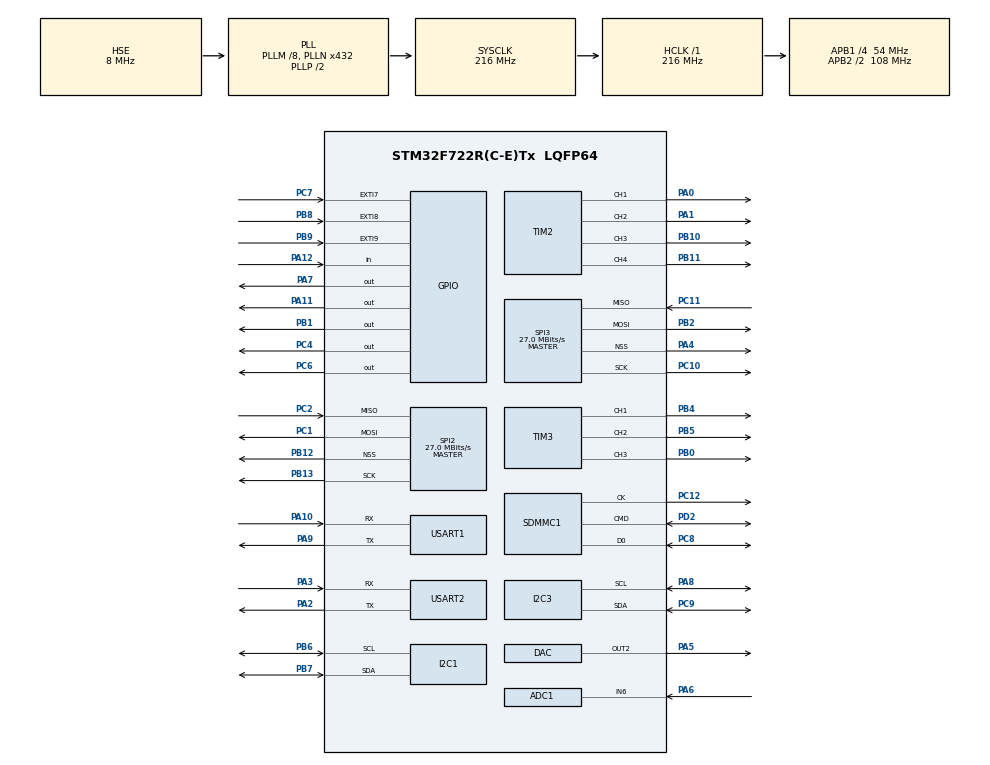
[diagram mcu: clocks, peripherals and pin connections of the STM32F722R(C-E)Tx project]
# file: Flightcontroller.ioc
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ADC1.Channel-1\#ChannelRegularConversion=ADC_CHANNEL_6
ADC1.NbrOfConversionFlag=1
ADC1.Rank-1\#ChannelRegularConversion=1
ADC1.SamplingTime-1\#ChannelRegularConversion=ADC_SAMPLETIME_3CYCLES
ADC1.master=1
I2C1.Timing=0x20404768
I2C3.Timing=0x20404768
Mcu.Family=STM32F7
Mcu.Name=STM32F722R(C-E)Tx
Mcu.Package=LQFP64
NVIC.PriorityGroup=NVIC_PRIORITYGROUP_4
PA0-WKUP.Signal=S_TIM2_CH1_ETR
PA1.Signal=S_TIM2_CH2
PA10.Mode=Asynchronous
PA10.Signal=USART1_RX
PA11.Signal=GPIO_Output
PA12.Signal=GPIO_Input
PA13.Mode=Serial_Wire
PA13.Signal=SYS_JTMS-SWDIO
PA14.Mode=Serial_Wire
PA14.Signal=SYS_JTCK-SWCLK
PA2.Mode=Asynchronous
PA2.Signal=USART2_TX
PA3.Mode=Asynchronous
PA3.Signal=USART2_RX
PA4.Mode=NSS_Signal_Hard_Output
PA4.Signal=SPI3_NSS
PA5.Signal=COMP_DAC2_group
PA6.Signal=ADCx_IN6
PA7.Signal=GPIO_Output
PA8.Mode=I2C
PA8.Signal=I2C3_SCL
PA9.Mode=Asynchronous
PA9.Signal=USART1_TX
PB0.Signal=S_TIM3_CH3
PB1.Signal=GPIO_Output
PB10.Signal=S_TIM2_CH3
PB11.Signal=S_TIM2_CH4
PB12.Mode=NSS_Signal_Hard_Output
PB12.Signal=SPI2_NSS
PB13.Mode=Full_Duplex_Master
PB13.Signal=SPI2_SCK
PB2.Mode=Full_Duplex_Master
PB2.Signal=SPI3_MOSI
PB4.Signal=S_TIM3_CH1
PB5.Signal=S_TIM3_CH2
PB6.Mode=I2C
PB6.Signal=I2C1_SCL
PB7.Mode=I2C
PB7.Signal=I2C1_SDA
PB8.Signal=GPXTI8
PB9.Signal=GPXTI9
PC1.Mode=Full_Duplex_Master
PC1.Signal=SPI2_MOSI
PC10.Mode=Full_Duplex_Master
PC10.Signal=SPI3_SCK
PC11.Mode=Full_Duplex_Master
PC11.Signal=SPI3_MISO
PC12.Mode=SD_1_bit
PC12.Signal=SDMMC1_CK
PC2.Mode=Full_Duplex_Master
PC2.Signal=SPI2_MISO
PC4.Signal=GPIO_Output
PC6.Signal=GPIO_Output
PC7.Signal=GPXTI7
PC8.Mode=SD_1_bit
PC8.Signal=SDMMC1_D0
PC9.Mode=I2C
PC9.Signal=I2C3_SDA
PD2.Mode=SD_1_bit
PD2.Signal=SDMMC1_CMD
PH0-OSC_IN.Mode=HSE-External-Oscillator
PH0-OSC_IN.Signal=RCC_OSC_IN
PH1-OSC_OUT.Mode=HSE-External-Oscillator
PH1-OSC_OUT.Signal=RCC_OSC_OUT
ProjectManager.HeapSize=0x200
ProjectManager.StackSize=0x400
ProjectManager.TargetToolchain=STM32CubeIDE
RCC.AHBFreq_Value=216000000
RCC.APB1CLKDivider=RCC_HCLK_DIV4
RCC.APB1Freq_Value=54000000
RCC.APB1TimFreq_Value=108000000
RCC.APB2CLKDivider=RCC_HCLK_DIV2
RCC.APB2Freq_Value=108000000
RCC.APB2TimFreq_Value=216000000
RCC.CortexFreq_Value=216000000
RCC.HCLKFreq_Value=216000000
RCC.HSE_VALUE=8000000
RCC.HSI_VALUE=16000000
RCC.LSE_VALUE=32768
RCC.PLLM=8
RCC.PLLN=432
RCC.PLLQ=9
RCC.PLLSourceVirtual=RCC_PLLSOURCE_HSE
RCC.SDMMCClockSelection=RCC_SDMMC1CLKSOURCE_CLK48
RCC.SYSCLKFreq_VALUE=216000000
RCC.SYSCLKSource=RCC_SYSCLKSOURCE_PLLCLK
RCC.USBFreq_Value=48000000
RCC.VCOOutputFreq_Value=432000000
SH.ADCx_IN6.0=ADC1_IN6,IN6
SH.COMP_DAC2_group.0=DAC_OUT2,DAC_OUT2
SH.S_TIM2_CH1_ETR.0=TIM2_CH1,PWM Generation1 CH1
SH.S_TIM2_CH2.0=TIM2_CH2,PWM Generation2 CH2
SH.S_TIM2_CH3.0=TIM2_CH3,PWM Generation3 CH3
SH.S_TIM2_CH4.0=TIM2_CH4,PWM Generation4 CH4
SH.S_TIM3_CH1.0=TIM3_CH1,PWM Generation1 CH1
SH.S_TIM3_CH2.0=TIM3_CH2,PWM Generation2 CH2
SH.S_TIM3_CH3.0=TIM3_CH3,PWM Generation3 CH3
SPI2.CalculateBaudRate=27.0 MBits/s
SPI2.Direction=SPI_DIRECTION_2LINES
SPI2.Mode=SPI_MODE_MASTER
SPI2.VirtualNSS=VM_NSSHARD
SPI2.VirtualType=VM_MASTER
SPI3.CalculateBaudRate=27.0 MBits/s
SPI3.Direction=SPI_DIRECTION_2LINES
SPI3.Mode=SPI_MODE_MASTER
SPI3.VirtualNSS=VM_NSSHARD
SPI3.VirtualType=VM_MASTER
TIM2.Channel-PWM\ Generation1\ CH1=TIM_CHANNEL_1
TIM2.Channel-PWM\ Generation2\ CH2=TIM_CHANNEL_2
TIM2.Channel-PWM\ Generation3\ CH3=TIM_CHANNEL_3
TIM2.Channel-PWM\ Generation4\ CH4=TIM_CHANNEL_4
TIM3.Channel-PWM\ Generation1\ CH1=TIM_CHANNEL_1
TIM3.Channel-PWM\ Generation2\ CH2=TIM_CHANNEL_2
TIM3.Channel-PWM\ Generation3\ CH3=TIM_CHANNEL_3
USART1.VirtualMode-Asynchronous=VM_ASYNC
USART2.VirtualMode-Asynchronous=VM_ASYNC
VP_FATFS_VS_SDIO.Mode=SDIO
VP_TIM2_VS_ClockSourceINT.Mode=Internal
board=custom

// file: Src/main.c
/* USER CODE BEGIN Header */
/**
  ******************************************************************************
  * @file           : main.c
  * @brief          : Main program body
  ******************************************************************************
  * @attention
  *
  * <h2><center>&copy; Copyright (c) 2019 STMicroelectronics.
  * All rights reserved.</center></h2>
  *
  * This software component is licensed by ST under BSD 3-Clause license,
  * the "License"; You may not use this file except in compliance with the
  * License. You may obtain a copy of the License at:
  *                        opensource.org/licenses/BSD-3-Clause
  *
  ******************************************************************************
  */
/* USER CODE END Header */

#include "main.h"
#include <stdio.h>
#include "adc.h"
#include "dac.h"
#include "fatfs.h"
#include "i2c.h"
#include "sdmmc.h"
#include "spi.h"
#include "tim.h"
#include "usart.h"
#include "gpio.h"

void SystemClock_Config(void);

int main(void)
{

  /* MCU Configuration--------------------------------------------------------*/

  /* Reset of all peripherals, Initializes the Flash interface and the Systick. */
  HAL_Init();

  /* Configure the system clock */
  SystemClock_Config();

  /* Initialize all configured peripherals */
  MX_GPIO_Init();
  MX_I2C1_Init();
  MX_SDMMC1_SD_Init();
  MX_SPI2_Init();
  MX_USART1_UART_Init();
  MX_USART2_UART_Init();
  MX_FATFS_Init();
  MX_I2C3_Init();
  MX_TIM2_Init();
  MX_DAC_Init();
  MX_SPI3_Init();
  MX_ADC1_Init();
  MX_TIM3_Init();
  /* USER CODE BEGIN 2 */
  HAL_GPIO_TogglePin(GPIOA, GPIO_PIN_7);
  /* USER CODE END 2 */

  /* Infinite loop */
  /* USER CODE BEGIN WHILE */
  while (1)
  {
	  char txt[32] = "Hello World \r\n";
	  HAL_GPIO_TogglePin(GPIOA, GPIO_PIN_7);
	  HAL_UART_Transmit(&huart1,(uint8_t*)txt,32,100);
	  HAL_Delay(100);
    /* USER CODE END WHILE */

  }
}

void SystemClock_Config(void)
{
  RCC_OscInitTypeDef RCC_OscInitStruct = {0};
  RCC_ClkInitTypeDef RCC_ClkInitStruct = {0};
  RCC_PeriphCLKInitTypeDef PeriphClkInitStruct = {0};

  /** Configure the main internal regulator output voltage
  */
  __HAL_RCC_PWR_CLK_ENABLE();
  __HAL_PWR_VOLTAGESCALING_CONFIG(PWR_REGULATOR_VOLTAGE_SCALE1);
  /** Initializes the CPU, AHB and APB busses clocks
  */
  RCC_OscInitStruct.OscillatorType = RCC_OSCILLATORTYPE_HSE;
  RCC_OscInitStruct.HSEState = RCC_HSE_ON;
  RCC_OscInitStruct.PLL.PLLState = RCC_PLL_ON;
  RCC_OscInitStruct.PLL.PLLSource = RCC_PLLSOURCE_HSE;
  RCC_OscInitStruct.PLL.PLLM = 8;
  RCC_OscInitStruct.PLL.PLLN = 432;
  RCC_OscInitStruct.PLL.PLLP = RCC_PLLP_DIV2;
  RCC_OscInitStruct.PLL.PLLQ = 9;
  if (HAL_RCC_OscConfig(&RCC_OscInitStruct) != HAL_OK)
  {
    Error_Handler();
  }
  /** Activate the Over-Drive mode
  */
  if (HAL_PWREx_EnableOverDrive() != HAL_OK)
  {
    Error_Handler();
  }
  /** Initializes the CPU, AHB and APB busses clocks
  */
  RCC_ClkInitStruct.ClockType = RCC_CLOCKTYPE_HCLK|RCC_CLOCKTYPE_SYSCLK
                              |RCC_CLOCKTYPE_PCLK1|RCC_CLOCKTYPE_PCLK2;
  RCC_ClkInitStruct.SYSCLKSource = RCC_SYSCLKSOURCE_PLLCLK;
  RCC_ClkInitStruct.AHBCLKDivider = RCC_SYSCLK_DIV1;
  RCC_ClkInitStruct.APB1CLKDivider = RCC_HCLK_DIV4;
  RCC_ClkInitStruct.APB2CLKDivider = RCC_HCLK_DIV2;

  if (HAL_RCC_ClockConfig(&RCC_ClkInitStruct, FLASH_LATENCY_7) != HAL_OK)
  {
    Error_Handler();
  }
  PeriphClkInitStruct.PeriphClockSelection = RCC_PERIPHCLK_USART1|RCC_PERIPHCLK_USART2
                              |RCC_PERIPHCLK_I2C1|RCC_PERIPHCLK_I2C3
                              |RCC_PERIPHCLK_SDMMC1|RCC_PERIPHCLK_CLK48;
  PeriphClkInitStruct.Usart1ClockSelection = RCC_USART1CLKSOURCE_PCLK2;
  PeriphClkInitStruct.Usart2ClockSelection = RCC_USART2CLKSOURCE_PCLK1;
  PeriphClkInitStruct.I2c1ClockSelection = RCC_I2C1CLKSOURCE_PCLK1;
  PeriphClkInitStruct.I2c3ClockSelection = RCC_I2C3CLKSOURCE_PCLK1;
  PeriphClkInitStruct.Clk48ClockSelection = RCC_CLK48SOURCE_PLL;
  PeriphClkInitStruct.Sdmmc1ClockSelection = RCC_SDMMC1CLKSOURCE_CLK48;
  if (HAL_RCCEx_PeriphCLKConfig(&PeriphClkInitStruct) != HAL_OK)
  {
    Error_Handler();
  }
}

void Error_Handler(void)
{
}

/************************ (C) COPYRIGHT STMicroelectronics *****END OF FILE****/
